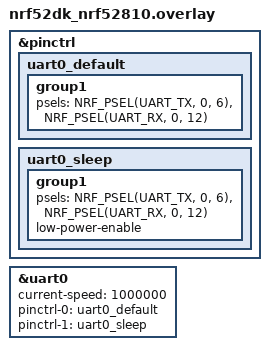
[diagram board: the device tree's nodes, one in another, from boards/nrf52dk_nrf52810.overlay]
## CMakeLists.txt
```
#
# Copyright (c) 2018 Nordic Semiconductor
#
# SPDX-License-Identifier: LicenseRef-Nordic-5-Clause
#
cmake_minimum_required(VERSION 3.20.0)

find_package(Zephyr REQUIRED HINTS $ENV{ZEPHYR_BASE})
project(EYE_AD8221)

# NORDIC SDK APP START
target_sources(app PRIVATE
  src/main.c
  src/emg_notch.c
  src/emg_sampler.c
  src/emg_uart_stream.c
  src/emg_ble_stream.c
  src/fatal_hook.c
)

# NORDIC SDK APP END
```

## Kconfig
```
#
# Copyright (c) 2018 Nordic Semiconductor
#
# SPDX-License-Identifier: LicenseRef-Nordic-5-Clause
#

source "Kconfig.zephyr"

menu "Nordic LED-Button BLE GATT service sample"

config BT_LBS_SECURITY_ENABLED
	bool "Enable security"
	default y
	select BT_SMP
	select BT_SETTINGS
	select FLASH
	select FLASH_PAGE_LAYOUT
	select FLASH_MAP
	select ZMS if (SOC_FLASH_NRF_RRAM || SOC_FLASH_NRF_MRAM)
	select NVS if !(SOC_FLASH_NRF_RRAM || SOC_FLASH_NRF_MRAM)
	select SETTINGS
	help
	  "Enable BLE security for the LED-Button service"

config EYE_BLE_STREAM_HZ
	int "BLE stream rate (Hz)"
	range 50 1000
	default 200
	help
	  Sample rate in samples/second delivered to the BLE client (may be packed
	  into fewer notifications).

config EYE_BLE_PACKET_HZ
	int "BLE notification packet rate (Hz)"
	range 1 200
	default 1
	help
	  Notification packets per second. Each packet carries multiple samples so
	  that EYE_BLE_STREAM_HZ samples/s are delivered with lower notify rate.

config EYE_BLE_STREAM_DISABLED
	bool "Disable BLE stream queue (debug via UART/RTT only)"
	default n
	help
	  When set, the sampler will not enqueue samples for BLE streaming, avoiding
	  queue drops while debugging over UART/RTT.

config EYE_ADC_SAMPLE_RATE_HZ
	int "ADC sample rate (Hz)"
	range 500 4000
	default 1000
	help
	  ADC sampling rate used on the MCU. Must be a multiple of EYE_BLE_STREAM_HZ.

config EYE_NOTCH_FREQ_HZ
	int "Notch center frequency (Hz)"
	range 50 60
	default 50
	help
	  50 Hz or 60 Hz mains notch.

config EYE_NOTCH_ENABLED
	bool "Enable notch filter"
	default y
	help
	  Enable/disable the MCU-side 2nd order IIR notch filter. Disabling keeps
	  the code available but streams raw (unfiltered) samples.

config EYE_NOTCH_Q
	int "Notch Q (approx)"
	range 20 35
	default 30
	help
	  Notch filter Q. Coefficients are precomputed for Q=20/25/30/35 and the
	  closest value is selected.

config EYE_NOTCH_DOUBLE
	bool "Apply notch twice (4th-order equivalent)"
	default n
	depends on EYE_NOTCH_ENABLED
	help
	  If enabled, run the notch filter twice (cascaded) for deeper 50/60 Hz
	  rejection at the cost of a slightly wider notch and more attenuation
	  around the center frequency.

config EYE_ENVELOPE_ENABLED
	bool "Compute envelope/energy (rectified + low-pass) before streaming"
	default y
	help
	  Rectify (abs) the centered ADC sample and apply a first-order IIR
	  low-pass to obtain an envelope/energy channel before decimation.
	  This lowers bandwidth while preserving EMG strength trends.

config EYE_ENVELOPE_TAU_SHIFT
	int "Envelope IIR shift (time constant)"
	range 3 8
	default 5
	depends on EYE_ENVELOPE_ENABLED
	help
	  IIR update: env = env + ((rect - env) >> shift). Smaller shift = faster
	  response (shorter time constant). At 2 kHz, shift 5 ~16 ms.

config EYE_UART_STREAM
	bool "Stream ADC to UART for VOFA+"
	default n
	help
	  Stream raw ADC samples over the console UART using VOFA+ JustFloat
	  protocol (float32 + 0x0000807F tail). Note: do not mix with text logs.

config EYE_UART_STREAM_CENTERED
	bool "UART stream centered values"
	default n
	depends on EYE_UART_STREAM
	help
	  If enabled, stream (raw - 2048) as float; otherwise stream raw (0..4095).

config EYE_UART_STREAM_HZ
	int "UART stream frame rate (Hz)"
	range 10 2000
	default 500
	depends on EYE_UART_STREAM
	help
	  VOFA+ frame rate.

config EYE_UART_STREAM_CHANNELS
	int "UART stream channels"
	range 2 3
	default 3
	depends on EYE_UART_STREAM
	help
	  Fixed to 2-3 channels for VOFA+:
	  2: CH1 raw ADC, CH2 filtered/decimated
	  3: CH1 raw, CH2 filtered/decimated, CH3 notch-filtered (50/60 Hz)

config EYE_BLE_CONN_INTERVAL_MIN
	int "BLE conn interval min (1.25ms units)"
	range 6 3200
	default 6
	help
	  Requested minimum connection interval (8 => 10ms).

config EYE_BLE_CONN_INTERVAL_MAX
	int "BLE conn interval max (1.25ms units)"
	range 6 3200
	default 12
	help
	  Requested maximum connection interval (8 => 10ms).

endmenu
```

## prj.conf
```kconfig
#
# Copyright (c) 2018 Nordic Semiconductor
#
# SPDX-License-Identifier: LicenseRef-Nordic-5-Clause
#
CONFIG_BT=y
CONFIG_BT_PERIPHERAL=y
CONFIG_BT_DEVICE_NAME="EYE_AD8221"
CONFIG_BT_SMP=n
CONFIG_BT_SETTINGS=n
CONFIG_BT_LBS_SECURITY_ENABLED=n

# Keep the connection interval from being auto-changed to slow defaults.
CONFIG_BT_GAP_AUTO_UPDATE_CONN_PARAMS=n
CONFIG_BT_GAP_PERIPHERAL_PREF_PARAMS=y
CONFIG_BT_PERIPHERAL_PREF_MIN_INT=6
CONFIG_BT_PERIPHERAL_PREF_MAX_INT=12
CONFIG_BT_PERIPHERAL_PREF_LATENCY=0
CONFIG_BT_PERIPHERAL_PREF_TIMEOUT=400

# SAADC via NRFX (timer + PPI driven)
CONFIG_ADC=n
CONFIG_NRFX_SAADC=y
CONFIG_NRFX_TIMER2=y
CONFIG_NRFX_PPI=y

# BLE peripheral helpers
CONFIG_DK_LIBRARY=y

CONFIG_SYSTEM_WORKQUEUE_STACK_SIZE=1024
CONFIG_ISR_STACK_SIZE=1536

# UART (P0.06 TX / P0.12 RX via overlay) used for VOFA+ binary stream
CONFIG_SERIAL=y
CONFIG_NRFX_UARTE0=y

# Streaming + filtering (defaults)
CONFIG_EYE_BLE_STREAM_HZ=4000
CONFIG_EYE_BLE_PACKET_HZ=100
CONFIG_EYE_BLE_STREAM_DISABLED=n
CONFIG_EYE_ADC_SAMPLE_RATE_HZ=4000
CONFIG_EYE_NOTCH_FREQ_HZ=50
CONFIG_EYE_NOTCH_ENABLED=y
CONFIG_EYE_NOTCH_Q=25
CONFIG_EYE_NOTCH_DOUBLE=y
CONFIG_EYE_ENVELOPE_ENABLED=y
CONFIG_EYE_ENVELOPE_TAU_SHIFT=5
CONFIG_EYE_BLE_CONN_INTERVAL_MIN=6
CONFIG_EYE_BLE_CONN_INTERVAL_MAX=12

# VOFA+ UART stream (raw ADC + filtered sample)
CONFIG_EYE_UART_STREAM=y
CONFIG_EYE_UART_STREAM_CENTERED=n
CONFIG_EYE_UART_STREAM_HZ=2000
CONFIG_EYE_UART_STREAM_CHANNELS=3

# Keep UART clean for VOFA+ binary stream: route text output to RTT instead.
CONFIG_USE_SEGGER_RTT=y
CONFIG_RTT_CONSOLE=y
CONFIG_SEGGER_RTT_BUFFER_SIZE_UP=512
CONFIG_SEGGER_RTT_MAX_NUM_UP_BUFFERS=4
CONFIG_SEGGER_RTT_MAX_NUM_DOWN_BUFFERS=1
CONFIG_CONSOLE=y
CONFIG_PRINTK=y
CONFIG_UART_CONSOLE=n
CONFIG_BOOT_BANNER=n

# Increase TX capacity to sustain high notification rates even if the central
# selects a longer connection interval.
CONFIG_BT_CONN_TX_MAX=6
CONFIG_BT_L2CAP_TX_BUF_COUNT=6
CONFIG_BT_ATT_TX_COUNT=6
CONFIG_BT_BUF_ACL_TX_COUNT=6
CONFIG_BT_BUF_EVT_RX_COUNT=8

# Debug: crash visibility and assertions
CONFIG_FAULT_DUMP=2
CONFIG_ASSERT=y
CONFIG_DEBUG_OPTIMIZATIONS=y
CONFIG_RESET_ON_FATAL_ERROR=n
CONFIG_THREAD_STACK_INFO=y
CONFIG_STACK_SENTINEL=n
```

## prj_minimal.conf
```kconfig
# BEGIN Configurations from basic/minimal

CONFIG_BT=y
CONFIG_BT_PERIPHERAL=y
CONFIG_BT_DEVICE_NAME="EYE_AD8221"
CONFIG_BT_SMP=n
CONFIG_BT_SETTINGS=n
CONFIG_BT_LBS_SECURITY_ENABLED=n

# SAADC via NRFX (timer + PPI driven)
CONFIG_ADC=n
CONFIG_NRFX_SAADC=y
CONFIG_NRFX_TIMER2=y
CONFIG_NRFX_PPI=y
CONFIG_EYE_ADC_SAMPLE_RATE_HZ=2000

CONFIG_DK_LIBRARY=y

# Drivers and peripherals
CONFIG_I2C=n
CONFIG_WATCHDOG=n
CONFIG_GPIO=n
CONFIG_SPI=n
CONFIG_SERIAL=y

# Power management

# Interrupts
CONFIG_DYNAMIC_INTERRUPTS=n
CONFIG_IRQ_OFFLOAD=n

# Memory protection
CONFIG_THREAD_STACK_INFO=n
CONFIG_THREAD_CUSTOM_DATA=n
CONFIG_FPU=n

# Boot
CONFIG_NCS_BOOT_BANNER=n
CONFIG_BOOT_BANNER=n
CONFIG_BOOT_DELAY=0

# Console: keep UART0 clean for VOFA+ stream, route text output to RTT instead.
CONFIG_USE_SEGGER_RTT=y
CONFIG_RTT_CONSOLE=y
CONFIG_CONSOLE=y
CONFIG_PRINTK=y
CONFIG_UART_CONSOLE=n
CONFIG_EARLY_CONSOLE=n

# Build
CONFIG_SIZE_OPTIMIZATIONS=y

# ARM
CONFIG_ARM_MPU=n
# END Configurations from basic/minimal

# In order to correctly tune the stack sizes for the threads the following
# Configurations can enabled to print the current use:
# CONFIG_THREAD_NAME=y
# CONFIG_THREAD_ANALYZER=y
# CONFIG_THREAD_ANALYZER_AUTO=y
# CONFIG_THREAD_ANALYZER_RUN_UNLOCKED=y
# CONFIG_THREAD_ANALYZER_USE_PRINTK=y
# CONFIG_CONSOLE=y
# CONFIG_UART_CONSOLE=y
# CONFIG_SERIAL=y
# CONFIG_PRINTK=y

# Example output of thread analyzer
# SDC RX              : unused 816 usage 208 / 1024 (20 %)
# BT RX               : unused 1784 usage 416 / 2200 (18 %)
# BT TX               : unused 992 usage 544 / 1536 (35 %)
# thread_analyzer     : unused 136 usage 376 / 512 (73 %)
# sysworkq            : unused 1824 usage 224 / 2048 (10 %)
# MPSL signal         : unused 520 usage 504 / 1024 (49 %)
# idle 00             : unused 192 usage 64 / 256 (25 %)
# main                : unused 136 usage 888 / 1024 (86 %)
# Configurations set based on thread analyzer output.
CONFIG_BT_RX_STACK_SIZE=1024
CONFIG_BT_HCI_TX_STACK_SIZE_WITH_PROMPT=y
CONFIG_BT_HCI_TX_STACK_SIZE=640
CONFIG_SYSTEM_WORKQUEUE_STACK_SIZE=1536
CONFIG_MPSL_WORK_STACK_SIZE=640
CONFIG_IDLE_STACK_SIZE=128
CONFIG_ISR_STACK_SIZE=1024

# Disable features not needed
CONFIG_TIMESLICING=n
CONFIG_COMMON_LIBC_MALLOC=n
CONFIG_LOG=n
CONFIG_ASSERT=n

# Disable Bluetooth features not needed
CONFIG_BT_DEBUG_NONE=y
CONFIG_BT_ASSERT=n
CONFIG_BT_DATA_LEN_UPDATE=n
CONFIG_BT_PHY_UPDATE=n
CONFIG_BT_GATT_CACHING=n
CONFIG_BT_GATT_SERVICE_CHANGED=n
CONFIG_BT_GAP_AUTO_UPDATE_CONN_PARAMS=n
CONFIG_BT_GAP_PERIPHERAL_PREF_PARAMS=y
CONFIG_BT_PERIPHERAL_PREF_MIN_INT=6
CONFIG_BT_PERIPHERAL_PREF_MAX_INT=12
CONFIG_BT_PERIPHERAL_PREF_LATENCY=0
CONFIG_BT_PERIPHERAL_PREF_TIMEOUT=400
CONFIG_BT_SETTINGS_CCC_LAZY_LOADING=n
CONFIG_BT_HCI_VS=n

# Disable Bluetooth controller features not needed
CONFIG_BT_CTLR_PRIVACY=n
CONFIG_BT_CTLR_PHY_2M=n

# VOFA+ UART stream (raw ADC + BLE sample + BLE sent + err)
CONFIG_EYE_UART_STREAM=y
CONFIG_EYE_UART_STREAM_CENTERED=n
CONFIG_EYE_UART_STREAM_HZ=2000
CONFIG_EYE_UART_STREAM_CHANNELS=3

# BLE stream/packet rates
CONFIG_EYE_BLE_STREAM_HZ=200
CONFIG_EYE_BLE_PACKET_HZ=50

CONFIG_EYE_NOTCH_FREQ_HZ=50
CONFIG_EYE_NOTCH_ENABLED=y
CONFIG_EYE_NOTCH_Q=25
CONFIG_EYE_NOTCH_DOUBLE=n
CONFIG_EYE_ENVELOPE_ENABLED=y
CONFIG_EYE_ENVELOPE_TAU_SHIFT=5

# Reduce Bluetooth buffers
CONFIG_BT_BUF_EVT_DISCARDABLE_COUNT=1
CONFIG_BT_BUF_EVT_DISCARDABLE_SIZE=43
CONFIG_BT_BUF_EVT_RX_COUNT=8

CONFIG_BT_CONN_TX_MAX=6
CONFIG_BT_L2CAP_TX_BUF_COUNT=6
CONFIG_BT_ATT_TX_COUNT=6
CONFIG_BT_BUF_ACL_TX_COUNT=6
CONFIG_BT_BUF_ACL_TX_SIZE=27
```

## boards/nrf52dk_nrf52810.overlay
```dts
#include <zephyr/dt-bindings/pinctrl/nrf-pinctrl.h>

&pinctrl {
	uart0_default: uart0_default {
		group1 {
			psels = <NRF_PSEL(UART_TX, 0, 6)>,
				<NRF_PSEL(UART_RX, 0, 12)>;
		};
	};

	uart0_sleep: uart0_sleep {
		group1 {
			psels = <NRF_PSEL(UART_TX, 0, 6)>,
				<NRF_PSEL(UART_RX, 0, 12)>;
			low-power-enable;
		};
	};
};

&uart0 {
	status = "okay";
	current-speed = <1000000>;
	pinctrl-0 = <&uart0_default>;
	pinctrl-1 = <&uart0_sleep>;
	pinctrl-names = "default", "sleep";
};
```

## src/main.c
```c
/*
 * Copyright (c) 2018 Nordic Semiconductor ASA
 *
 * SPDX-License-Identifier: LicenseRef-Nordic-5-Clause
 */

#include <zephyr/types.h>
#include <stddef.h>
#include <string.h>
#include <errno.h>
#include <zephyr/sys/printk.h>
#include <zephyr/sys/byteorder.h>
#include <zephyr/sys/util.h>
#include <zephyr/kernel.h>

#include <zephyr/bluetooth/bluetooth.h>
#include <zephyr/bluetooth/hci.h>
#include <zephyr/bluetooth/conn.h>
#include <zephyr/bluetooth/uuid.h>
#include <zephyr/bluetooth/gatt.h>

#include <dk_buttons_and_leds.h>

#include "emg_sampler.h"
#include "emg_uart_stream.h"
#include "emg_ble_stream.h"

/*
 * Application entry point.
 *
 * Responsibilities:
 * - Initialize BLE GATT service for single-sample read/notify + stream notify.
 * - Start the SAADC sampling pipeline and UART binary streaming.
 * - Maintain BLE advertising/connection state and send periodic stats.
 */
#define DEVICE_NAME             CONFIG_BT_DEVICE_NAME
#define DEVICE_NAME_LEN         (sizeof(DEVICE_NAME) - 1)
#define DEVICE_NAME_SHORT_MAX   8
#define DEVICE_NAME_SHORT_LEN   MIN(DEVICE_NAME_LEN, DEVICE_NAME_SHORT_MAX)


#define RUN_STATUS_LED          DK_LED1
#define CON_STATUS_LED          DK_LED2
#define RUN_LED_BLINK_INTERVAL  1000

static struct k_work adv_work;

#define NOTIFY_INTERVAL_MS_DEFAULT  (1000 / CONFIG_EYE_BLE_PACKET_HZ)
#define NOTIFY_INTERVAL_MS_MIN      NOTIFY_INTERVAL_MS_DEFAULT

BUILD_ASSERT(CONFIG_EYE_BLE_STREAM_HZ % CONFIG_EYE_BLE_PACKET_HZ == 0,
	     "EYE_BLE_STREAM_HZ must be a multiple of EYE_BLE_PACKET_HZ");
#define STREAM_SAMPLES_PER_PACKET   (CONFIG_EYE_BLE_STREAM_HZ / CONFIG_EYE_BLE_PACKET_HZ)

static uint16_t notify_interval_ms = NOTIFY_INTERVAL_MS_DEFAULT;
static struct k_work_delayable notify_work;
static uint32_t last_stats_uptime_ms;
static uint32_t stat_notify_attempts;
static uint32_t stat_notify_ok;
static uint32_t stat_notify_err;
static uint32_t last_sampler_log_ms;

/* BLE UUIDs */
#define BT_UUID_EYE_SVC_VAL \
	BT_UUID_128_ENCODE(0x0000ad82, 0x1212, 0xefde, 0x1523, 0x785feabcd123)

#define BT_UUID_EYE_ADC_VAL \
	BT_UUID_128_ENCODE(0x0000ad83, 0x1212, 0xefde, 0x1523, 0x785feabcd123)

#define BT_UUID_EYE_CFG_VAL \
	BT_UUID_128_ENCODE(0x0000ad84, 0x1212, 0xefde, 0x1523, 0x785feabcd123)

#define BT_UUID_EYE_STREAM_VAL \
	BT_UUID_128_ENCODE(0x0000ad85, 0x1212, 0xefde, 0x1523, 0x785feabcd123)

#define BT_UUID_EYE_SVC  BT_UUID_DECLARE_128(BT_UUID_EYE_SVC_VAL)
#define BT_UUID_EYE_ADC  BT_UUID_DECLARE_128(BT_UUID_EYE_ADC_VAL)
#define BT_UUID_EYE_CFG  BT_UUID_DECLARE_128(BT_UUID_EYE_CFG_VAL)
#define BT_UUID_EYE_STREAM  BT_UUID_DECLARE_128(BT_UUID_EYE_STREAM_VAL)

static bool notify_enabled;
static bool stream_notify_enabled;
static struct bt_conn *default_conn;

static void request_fast_conn_params(struct bt_conn *conn)
{
	struct bt_le_conn_param param = {
		.interval_min = CONFIG_EYE_BLE_CONN_INTERVAL_MIN,
		.interval_max = CONFIG_EYE_BLE_CONN_INTERVAL_MAX,
		.latency = 0,
		.timeout = 400,
	};

	int err = bt_conn_le_param_update(conn, &param);
	if (err) {
		printk("Conn param update request failed (err %d)\n", err);
	}
}

static const struct bt_data ad[] = {
	BT_DATA_BYTES(BT_DATA_FLAGS, (BT_LE_AD_GENERAL | BT_LE_AD_NO_BREDR)),
	BT_DATA_BYTES(BT_DATA_UUID128_ALL, BT_UUID_EYE_SVC_VAL),
	BT_DATA(BT_DATA_NAME_SHORTENED, DEVICE_NAME, DEVICE_NAME_SHORT_LEN),
};

static const struct bt_data sd[] = {
	BT_DATA(BT_DATA_NAME_COMPLETE, DEVICE_NAME, DEVICE_NAME_LEN),
};

static void notify_work_handler(struct k_work *work);

/*
 * CCC handlers toggle notifications for the single-sample and stream
 * characteristics. Both of them share the same notify work item and interval.
 */
static void ccc_cfg_changed(const struct bt_gatt_attr *attr, uint16_t value)
{
	notify_enabled = (value == BT_GATT_CCC_NOTIFY);

	if (!default_conn) {
		return;
	}

	if (!notify_enabled || notify_interval_ms == 0) {
		(void)k_work_cancel_delayable(&notify_work);
		return;
	}

	request_fast_conn_params(default_conn);
	k_work_reschedule(&notify_work, K_NO_WAIT);
}

static void stream_ccc_cfg_changed(const struct bt_gatt_attr *attr, uint16_t value)
{
	ARG_UNUSED(attr);
	stream_notify_enabled = (value == BT_GATT_CCC_NOTIFY);

	if (!default_conn) {
		return;
	}

	if (!stream_notify_enabled || notify_interval_ms == 0) {
		(void)k_work_cancel_delayable(&notify_work);
		return;
	}

	request_fast_conn_params(default_conn);
	k_work_reschedule(&notify_work, K_NO_WAIT);
}

static ssize_t read_adc(struct bt_conn *conn, const struct bt_gatt_attr *attr,
			void *buf, uint16_t len, uint16_t offset)
{
	/* Read handler returns the latest filtered sample (little-endian). */
	uint16_t sample = emg_sampler_get_latest_sample_u16();
	uint16_t sample_le = sys_cpu_to_le16(sample);

	return bt_gatt_attr_read(conn, attr, buf, len, offset, &sample_le,
				 sizeof(sample_le));
}

static ssize_t write_cfg(struct bt_conn *conn, const struct bt_gatt_attr *attr,
			 const void *buf, uint16_t len, uint16_t offset,
			 uint8_t flags)
{
	if (offset != 0) {
		return BT_GATT_ERR(BT_ATT_ERR_INVALID_OFFSET);
	}

	if (len != sizeof(uint16_t)) {
		return BT_GATT_ERR(BT_ATT_ERR_INVALID_ATTRIBUTE_LEN);
	}

	uint16_t interval = sys_get_le16(buf);

	/* Clamp to a safe interval range to avoid flooding or slowing down too far. */
	if (interval != 0 && interval < NOTIFY_INTERVAL_MS_MIN) {
		interval = NOTIFY_INTERVAL_MS_MIN;
	}

	/* Keep MCU default rate unless the client explicitly asks for faster. */
	if (interval != 0 && interval > NOTIFY_INTERVAL_MS_DEFAULT) {
		interval = NOTIFY_INTERVAL_MS_DEFAULT;
	}

	notify_interval_ms = interval;

	if (!default_conn) {
		return len;
	}

	if (notify_interval_ms == 0 || !notify_enabled) {
		(void)k_work_cancel_delayable(&notify_work);
	} else {
		k_work_reschedule(&notify_work, K_NO_WAIT);
	}

	return len;
}

BT_GATT_SERVICE_DEFINE(eye_svc,
	BT_GATT_PRIMARY_SERVICE(BT_UUID_EYE_SVC),
	BT_GATT_CHARACTERISTIC(BT_UUID_EYE_ADC, BT_GATT_CHRC_READ | BT_GATT_CHRC_NOTIFY,
			       BT_GATT_PERM_READ, read_adc, NULL, NULL),
	BT_GATT_CCC(ccc_cfg_changed, BT_GATT_PERM_READ | BT_GATT_PERM_WRITE),
	BT_GATT_CHARACTERISTIC(BT_UUID_EYE_CFG, BT_GATT_CHRC_WRITE,
			       BT_GATT_PERM_WRITE, NULL, write_cfg, NULL),
	BT_GATT_CHARACTERISTIC(BT_UUID_EYE_STREAM, BT_GATT_CHRC_NOTIFY,
			       BT_GATT_PERM_NONE, NULL, NULL, NULL),
	BT_GATT_CCC(stream_ccc_cfg_changed, BT_GATT_PERM_READ | BT_GATT_PERM_WRITE),
);

static void notify_work_handler(struct k_work *work)
{
	ARG_UNUSED(work);

	/* Work item is shared by both notify paths and reschedules itself. */
	if (!default_conn || notify_interval_ms == 0 || (!notify_enabled && !stream_notify_enabled)) {
		return;
	}

	uint16_t effective_interval_ms = notify_interval_ms;
	if (!stream_notify_enabled && notify_enabled && (notify_interval_ms == NOTIFY_INTERVAL_MS_DEFAULT)) {
		effective_interval_ms = MAX(1U, (1000U / CONFIG_EYE_BLE_STREAM_HZ));
	}

	uint32_t now_ms = (uint32_t)k_uptime_get_32();
	if (last_stats_uptime_ms == 0) {
		last_stats_uptime_ms = now_ms;
	}
	if (!IS_ENABLED(CONFIG_UART_CONSOLE) && (now_ms - last_stats_uptime_ms) >= 1000U) {
		printk("BLE notify: interval=%ums attempts=%u ok=%u err=%u (target=%uHz)\n",
		       effective_interval_ms, stat_notify_attempts, stat_notify_ok,
		       stat_notify_err, CONFIG_EYE_BLE_STREAM_HZ);
		printk("BLE ccc: ad83=%u ad85=%u mtu=%u qdrop=%u nerr=%u clip_lo=%u clip_hi=%u\n",
		       notify_enabled ? 1 : 0,
		       stream_notify_enabled ? 1 : 0,
		       bt_gatt_get_mtu(default_conn),
		       emg_sampler_get_stream_drop_count(),
		       emg_ble_stream_get_notify_err(),
		       emg_sampler_get_clip_lo(),
		       emg_sampler_get_clip_hi());
		stat_notify_attempts = 0;
		stat_notify_ok = 0;
		stat_notify_err = 0;
		last_stats_uptime_ms = now_ms;
	}

	if (stream_notify_enabled) {
		/*
		 * Stream notify mode:
		 * - Pulls a packet of samples from the sampler stream queue.
		 * - Chunks the packet to fit the current MTU.
		 * - Spreads chunks across the notify interval to reduce bursts.
		 */
		static uint32_t period_end_ms;
		static uint32_t staged_first_seq;
		static struct emg_stream_pair staged_samples[STREAM_SAMPLES_PER_PACKET];
		static uint32_t staged_count;
		static uint32_t staged_off;

		const uint16_t mtu = bt_gatt_get_mtu(default_conn);
		const uint16_t max_payload = (mtu > 3U) ? (mtu - 3U) : 0U;
		const uint16_t max_samples_per_notify =
			(max_payload > 5U) ? (uint16_t)((max_payload - 5U) / 4U) : 0U;

		if (max_samples_per_notify == 0U) {
			k_work_schedule(&notify_work, K_MSEC(notify_interval_ms));
			return;
		}

		/* Stage a new packet when the previous one has been fully sent. */
		if (staged_off >= staged_count) {
			if (period_end_ms != 0U && (int32_t)(now_ms - period_end_ms) < 0) {
				k_work_schedule(&notify_work, K_MSEC(period_end_ms - now_ms));
				return;
			}

			staged_off = 0;
			staged_count = emg_sampler_pop_stream(&staged_first_seq, staged_samples,
							     STREAM_SAMPLES_PER_PACKET);
			if (staged_count == 0U) {
				period_end_ms = 0U;
				k_work_schedule(&notify_work, K_MSEC(5));
				return;
			}
			period_end_ms = now_ms + effective_interval_ms;
		}

		const uint32_t remaining = staged_count - staged_off;
		const uint32_t chunk = MIN(remaining, (uint32_t)max_samples_per_notify);

		uint8_t payload[5 + 4 * STREAM_SAMPLES_PER_PACKET];
		const uint32_t first_seq = staged_first_seq + staged_off;

		sys_put_le32(first_seq, &payload[0]);
		payload[4] = (uint8_t)chunk;
		for (uint32_t i = 0; i < chunk; i++) {
			const struct emg_stream_pair *pair = &staged_samples[staged_off + i];
			sys_put_le16(pair->filtered, &payload[5 + 4 * i]);
			sys_put_le16(pair->envelope, &payload[5 + 4 * i + 2]);
		}

		stat_notify_attempts++;
		int err = bt_gatt_notify(default_conn, &eye_svc.attrs[7], payload, 5 + 2 * chunk);
		if (err) {
			stat_notify_err++;
			emg_ble_stream_note_notify_err();

			if (err == -ENOMEM || err == -EAGAIN) {
				k_work_schedule(&notify_work, K_MSEC(2));
				return;
			}

			k_work_schedule(&notify_work, K_MSEC(notify_interval_ms));
			return;
		}

		stat_notify_ok++;
		emg_ble_stream_note_notify_ok(chunk);
		emg_ble_stream_note_sent(first_seq + chunk - 1U,
					 staged_samples[staged_off + chunk - 1U].filtered);
		staged_off += chunk;

		if (staged_off < staged_count) {
			now_ms = (uint32_t)k_uptime_get_32();
			const uint32_t rem_samples = staged_count - staged_off;
			const uint32_t chunks_left =
				(rem_samples + max_samples_per_notify - 1U) / max_samples_per_notify;
			const uint32_t time_left_ms =
				(period_end_ms != 0U && (int32_t)(period_end_ms - now_ms) > 0)
					? (period_end_ms - now_ms)
					: 1U;
			const uint32_t chunk_period_ms = MAX(1U, time_left_ms / MAX(1U, chunks_left));
			k_work_schedule(&notify_work, K_MSEC(chunk_period_ms));
			return;
		}

		now_ms = (uint32_t)k_uptime_get_32();
		if (period_end_ms != 0U && (int32_t)(now_ms - period_end_ms) < 0) {
			k_work_schedule(&notify_work, K_MSEC(period_end_ms - now_ms));
		} else {
			k_work_schedule(&notify_work, K_NO_WAIT);
		}
		return;
	} else if (notify_enabled) {
		/* Single-sample notify mode (simple characteristic notify). */
		uint16_t sample = emg_sampler_get_latest_sample_u16();
		uint16_t sample_le = sys_cpu_to_le16(sample);

		stat_notify_attempts++;
		int err = bt_gatt_notify(default_conn, &eye_svc.attrs[2],
					 &sample_le, sizeof(sample_le));
		if (err) {
			stat_notify_err++;
		} else {
			stat_notify_ok++;
		}
	}

	k_work_schedule(&notify_work, K_MSEC(effective_interval_ms));
}

static void adv_work_handler(struct k_work *work)
{
	/* Deferred advertising start to keep startup ordering clean. */
	int err = bt_le_adv_start(BT_LE_ADV_CONN_FAST_2, ad, ARRAY_SIZE(ad), sd, ARRAY_SIZE(sd));

	if (err) {
		printk("Advertising failed to start (err %d)\n", err);
		return;
	}

	printk("Advertising successfully started\n");
}

static void advertising_start(void)
{
	k_work_submit(&adv_work);
}

static void connected(struct bt_conn *conn, uint8_t err)
{
	if (err) {
		printk("Connection failed, err 0x%02x %s\n", err, bt_hci_err_to_str(err));
		return;
	}

	printk("Connected\n");

	default_conn = bt_conn_ref(conn);
	dk_set_led_on(CON_STATUS_LED);

	request_fast_conn_params(conn);

	/* nRF52810 does not support LE 2M PHY; skip bt_conn_le_phy_update to avoid link error. */
}

static void disconnected(struct bt_conn *conn, uint8_t reason)
{
	printk("Disconnected, reason 0x%02x %s\n", reason, bt_hci_err_to_str(reason));

	notify_enabled = false;
	if (default_conn) {
		bt_conn_unref(default_conn);
		default_conn = NULL;
	}
	(void)k_work_cancel_delayable(&notify_work);

	dk_set_led_off(CON_STATUS_LED);
}

static void recycled_cb(void)
{
	printk("Connection object available from previous conn. Disconnect is complete!\n");
	advertising_start();
}

#if defined(CONFIG_BT_CONN)
static void le_param_updated(struct bt_conn *conn, uint16_t interval,
			     uint16_t latency, uint16_t timeout)
{
	ARG_UNUSED(conn);
	printk("LE params updated: interval %u (1.25ms), latency %u, timeout %u (10ms)\n",
	       interval, latency, timeout);
}
#endif

#ifdef CONFIG_BT_LBS_SECURITY_ENABLED
static void security_changed(struct bt_conn *conn, bt_security_t level,
			     enum bt_security_err err)
{
	char addr[BT_ADDR_LE_STR_LEN];

	bt_addr_le_to_str(bt_conn_get_dst(conn), addr, sizeof(addr));

	if (!err) {
		printk("Security changed: %s level %u\n", addr, level);
	} else {
		printk("Security failed: %s level %u err %d %s\n", addr, level, err,
		       bt_security_err_to_str(err));
	}
}
#endif

BT_CONN_CB_DEFINE(conn_callbacks) = {
	.connected        = connected,
	.disconnected     = disconnected,
	.recycled         = recycled_cb,
#if defined(CONFIG_BT_CONN)
	.le_param_updated = le_param_updated,
#endif
};

int main(void)
{
	int blink_status = 0;
	int err;
	uint32_t now_ms;

	/* Bring up console logging early for power-on visibility. */
	printk("Starting BLE ADC (P0.04) peripheral\n");
	printk("UART0 pins: TX=P0.06 RX=P0.12 (1000000)\n");
	printk("Stream target: %uHz (notify interval %ums)\n",
	       CONFIG_EYE_BLE_STREAM_HZ, NOTIFY_INTERVAL_MS_DEFAULT);
	printk("ADC sample rate: %u Hz\n", CONFIG_EYE_ADC_SAMPLE_RATE_HZ);

	err = dk_leds_init();
	if (err) {
		printk("LEDs init failed (err %d)\n", err);
		return 0;
	}

	err = bt_enable(NULL);
	if (err) {
		printk("Bluetooth init failed (err %d)\n", err);
		return 0;
	}

	printk("Bluetooth initialized\n");

	/* Start the sampling pipeline before enabling streaming outputs. */
	err = emg_sampler_init();
	if (err) {
		printk("Sampler init failed (err %d)\n", err);
		return 0;
	}

	/* UART stream uses a dedicated thread and binary frames. */
	err = emg_uart_stream_init();
	if (err) {
		printk("UART stream init failed (err %d)\n", err);
		return 0;
	}

	k_work_init(&adv_work, adv_work_handler);
	k_work_init_delayable(&notify_work, notify_work_handler);
	advertising_start();

	for (;;) {
		dk_set_led(RUN_STATUS_LED, (++blink_status) % 2);

		/* Once per second: print sampling and queue stats for troubleshooting. */
		now_ms = (uint32_t)k_uptime_get_32();
		if ((now_ms - last_sampler_log_ms) >= 1000U) {
			printk("ADC stats: raw=%u seq=%u drop=%u clip_lo=%u clip_hi=%u\n",
			       emg_sampler_get_latest_raw_u16(),
			       emg_sampler_get_latest_raw_seq(),
			       emg_sampler_get_stream_drop_count(),
			       emg_sampler_get_clip_lo(),
			       emg_sampler_get_clip_hi());
			printk("UART q: drop=%u hwm=%u\n",
			       emg_sampler_get_uart_drop(),
			       emg_sampler_get_uart_hwm());
			last_sampler_log_ms = now_ms;
		}

		k_sleep(K_MSEC(RUN_LED_BLINK_INTERVAL));
	}
}
```

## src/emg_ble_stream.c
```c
/*
 * SPDX-License-Identifier: LicenseRef-Nordic-5-Clause
 */

#include "emg_ble_stream.h"

#include <zephyr/sys/atomic.h>

static atomic_t last_sent_seq;
static atomic_t last_sent_sample_u16;
static atomic_t notify_ok;
static atomic_t notify_err;

/* Track the most recent streamed sequence/sample for diagnostics. */
void emg_ble_stream_note_sent(uint32_t seq, uint16_t sample)
{
	atomic_set(&last_sent_seq, (atomic_val_t)seq);
	atomic_set(&last_sent_sample_u16, (atomic_val_t)sample);
}

/* Accumulate how many samples were acknowledged as notified. */
void emg_ble_stream_note_notify_ok(uint32_t samples)
{
	for (uint32_t i = 0; i < samples; i++) {
		atomic_inc(&notify_ok);
	}
}

/* Count notify failures so we can log BLE link pressure. */
void emg_ble_stream_note_notify_err(void)
{
	atomic_inc(&notify_err);
}

uint32_t emg_ble_stream_get_last_sent_seq(void)
{
	return (uint32_t)atomic_get(&last_sent_seq);
}

uint16_t emg_ble_stream_get_last_sent_sample(void)
{
	return (uint16_t)atomic_get(&last_sent_sample_u16);
}

uint32_t emg_ble_stream_get_notify_ok(void)
{
	return (uint32_t)atomic_get(&notify_ok);
}

uint32_t emg_ble_stream_get_notify_err(void)
{
	return (uint32_t)atomic_get(&notify_err);
}
```

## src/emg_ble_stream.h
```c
/*
 * SPDX-License-Identifier: LicenseRef-Nordic-5-Clause
 */

#pragma once

#include <stdint.h>

/* Record the last sequence/sample that made it onto the BLE stream. */
void emg_ble_stream_note_sent(uint32_t seq, uint16_t sample);
/* Count the number of samples successfully notified. */
void emg_ble_stream_note_notify_ok(uint32_t samples);
/* Count a notify error (link congestion/MTU/backpressure). */
void emg_ble_stream_note_notify_err(void);

/* Diagnostics: last sent sequence/sample and notify stats. */
uint32_t emg_ble_stream_get_last_sent_seq(void);
uint16_t emg_ble_stream_get_last_sent_sample(void);
uint32_t emg_ble_stream_get_notify_ok(void);
uint32_t emg_ble_stream_get_notify_err(void);
```

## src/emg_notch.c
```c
/*
 * SPDX-License-Identifier: LicenseRef-Nordic-5-Clause
 */

#include "emg_notch.h"

#include <stddef.h>
#include <math.h>
#include <zephyr/sys/printk.h>

#ifndef M_PI
#define M_PI 3.14159265358979323846
#endif

struct coeff_entry {
	uint16_t fs_hz;
	uint8_t f0_hz;
	uint8_t q;
	int32_t b0;
	int32_t b1;
	int32_t b2;
	int32_t a1;
	int32_t a2;
};

/*
 * Precomputed biquad notch coefficients in Q30 for:
 * - fs: 1000/2000 Hz
 * - f0: 50/60 Hz
 * - Q: 20/25/30/35
 *
 * Coeffs follow the normalized form:
 *   y[n] = b0*x[n] + b1*x[n-1] + b2*x[n-2] - a1*y[n-1] - a2*y[n-2]
 */
static const struct coeff_entry coeff_table[] = {
	/* fs=1000, f0=50 */
	{ 1000, 50, 20, 1065510304, -2026721036, 1065510304, -2026721036, 1057278784 },
	{ 1000, 50, 25, 1067146496, -2029833258, 1067146496, -2029833258, 1060551168 },
	{ 1000, 50, 30, 1068240085, -2031913388, 1068240085, -2031913388, 1062738346 },
	{ 1000, 50, 35, 1069022593, -2033401807, 1069022593, -2033401807, 1064303363 },

	/* fs=1000, f0=60 */
	{ 1000, 60, 20, 1063950169, -1978471700, 1063950169, -1978471700, 1054158515 },
	{ 1000, 60, 25, 1065894188, -1982086704, 1065894188, -1982086704, 1058046551 },
	{ 1000, 60, 30, 1067194151, -1984504055, 1067194151, -1984504055, 1060646478 },
	{ 1000, 60, 35, 1068124640, -1986234348, 1068124640, -1986234348, 1062507455 },

	/* fs=2000, f0=50 */
	{ 2000, 50, 20, 1069558927, -2112781764, 1069558927, -2112781764, 1065376030 },
	{ 2000, 50, 25, 1070392897, -2114429169, 1070392897, -2114429169, 1067043970 },
	{ 2000, 50, 30, 1070949600, -2115528867, 1070949600, -2115528867, 1068157376 },
	{ 2000, 50, 35, 1071347600, -2116315066, 1071347600, -2116315066, 1068953376 },

	/* fs=2000, f0=60 */
	{ 2000, 60, 20, 1068735298, -2099610116, 1068735298, -2099610116, 1063728773 },
	{ 2000, 60, 25, 1069732865, -2101569910, 1069732865, -2101569910, 1065723906 },
	{ 2000, 60, 30, 1070398945, -2102878473, 1070398945, -2102878473, 1067056065 },
	{ 2000, 60, 35, 1070875224, -2103814159, 1070875224, -2103814159, 1068008624 },
};

/*
 * Pick the closest Q entry for a given fs/f0.
 * The table only supports the fixed fs/f0 pairs above.
 */
static const struct coeff_entry *find_best_coeff(uint32_t fs_hz, uint32_t f0_hz, uint32_t q)
{
	const struct coeff_entry *best = NULL;
	uint32_t best_dist = UINT32_MAX;

	for (size_t i = 0; i < (sizeof(coeff_table) / sizeof(coeff_table[0])); i++) {
		const struct coeff_entry *e = &coeff_table[i];

		if (e->fs_hz != fs_hz || e->f0_hz != f0_hz) {
			continue;
		}

		uint32_t dist = (e->q > q) ? (e->q - q) : (q - e->q);
		if (dist < best_dist) {
			best = e;
			best_dist = dist;
		}
	}

	return best;
}

/*
 * Fallback coefficient compute for arbitrary fs/f0/q (floating-point).
 * The resulting coefficients are converted to Q30 and used in the
 * integer biquad process function.
 */
static int compute_fallback_coeff(struct emg_notch_biquad_q30 *state,
				  uint32_t fs_hz, uint32_t f0_hz, uint32_t q)
{
	if (f0_hz == 0 || fs_hz == 0 || q == 0) {
		return -1;
	}

	double w0 = 2.0 * M_PI * ((double)f0_hz / (double)fs_hz);
	double cos_w0 = cos(w0);
	double alpha = sin(w0) / (2.0 * (double)q);

	double b0 = 1.0;
	double b1 = -2.0 * cos_w0;
	double b2 = 1.0;
	double a0 = 1.0 + alpha;
	double a1 = -2.0 * cos_w0;
	double a2 = 1.0 - alpha;

	/* Normalize by a0 */
	b0 /= a0;
	b1 /= a0;
	b2 /= a0;
	a1 /= a0;
	a2 /= a0;

	const double q30 = (double)(1ULL << 30);
	state->b0 = (int32_t)lrint(b0 * q30);
	state->b1 = (int32_t)lrint(b1 * q30);
	state->b2 = (int32_t)lrint(b2 * q30);
	state->a1 = (int32_t)lrint(a1 * q30);
	state->a2 = (int32_t)lrint(a2 * q30);
	emg_notch_reset(state);

	printk("Notch coeff computed (fs=%u f0=%u q=%u)\n", fs_hz, f0_hz, q);
	return 0;
}

void emg_notch_reset(struct emg_notch_biquad_q30 *state)
{
	if (!state) {
		return;
	}

	state->s1 = 0;
	state->s2 = 0;
}

int emg_notch_configure(struct emg_notch_biquad_q30 *state, uint32_t fs_hz,
			uint32_t f0_hz, uint32_t q)
{
	if (!state) {
		return -1;
	}

	/* Prefer precomputed coefficients when available; fall back otherwise. */
	const struct coeff_entry *e = find_best_coeff(fs_hz, f0_hz, q);
	if (!e) {
		return compute_fallback_coeff(state, fs_hz, f0_hz, q);
	}

	state->b0 = e->b0;
	state->b1 = e->b1;
	state->b2 = e->b2;
	state->a1 = e->a1;
	state->a2 = e->a2;
	emg_notch_reset(state);

	return 0;
}

int32_t emg_notch_process(struct emg_notch_biquad_q30 *state, int32_t x)
{
	/* Direct Form II Transposed, Q30 coefficients, integer samples (Q0). */
	int64_t acc = (int64_t)state->b0 * x + state->s1;
	int32_t y = (int32_t)(acc >> 30);

	state->s1 = (int64_t)state->b1 * x + state->s2 - (int64_t)state->a1 * y;
	state->s2 = (int64_t)state->b2 * x - (int64_t)state->a2 * y;

	return y;
}
```

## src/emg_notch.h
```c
/*
 * SPDX-License-Identifier: LicenseRef-Nordic-5-Clause
 */

#pragma once

#include <stdint.h>

struct emg_notch_biquad_q30 {
	/* Q30 biquad coefficients (normalized). */
	int32_t b0;
	int32_t b1;
	int32_t b2;
	int32_t a1;
	int32_t a2;

	/* Filter state (Direct Form II Transposed). */
	int64_t s1;
	int64_t s2;
};

/* Reset filter state to zero. */
void emg_notch_reset(struct emg_notch_biquad_q30 *state);
/* Configure coefficients for fs/f0/q; uses table or computed fallback. */
int emg_notch_configure(struct emg_notch_biquad_q30 *state, uint32_t fs_hz,
			uint32_t f0_hz, uint32_t q);
/* Process one sample (integer input, integer output). */
int32_t emg_notch_process(struct emg_notch_biquad_q30 *state, int32_t x);
```

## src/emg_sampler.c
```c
/*
 * SPDX-License-Identifier: LicenseRef-Nordic-5-Clause
 */

#include "emg_sampler.h"

#include "emg_notch.h"

#include <errno.h>

#include <zephyr/kernel.h>
#include <zephyr/irq.h>
#include <zephyr/sys/atomic.h>
#include <zephyr/sys/util.h>
#include <zephyr/sys/printk.h>
#include <nrfx_timer.h>
#include <nrfx_ppi.h>
#include <hal/nrf_saadc.h>
#include <nrfx_saadc.h>

#ifndef NRFX_SAADC_CONFIG_IRQ_PRIORITY
#define NRFX_SAADC_CONFIG_IRQ_PRIORITY 6
#endif

/*
 * SAADC sampler pipeline.
 *
 * Data flow:
 * - TIMER2 compares at fs -> PPI -> SAADC SAMPLE
 * - SAADC EasyDMA fills double buffers
 * - SAADC DONE ISR processes samples:
 *   raw -> notch -> high-pass (DC block) -> optional envelope
 * - Outputs:
 *   - Latest values (atomics) for BLE read/notify
 *   - Stream queue (decimated) for BLE streaming
 *   - UART queue (full-rate) for binary streaming
 */

/* SAADC (P0.04 = AIN2 on nRF52) */
#define ADC_CHANNEL_ID      0
#define ADC_INPUT           NRF_SAADC_INPUT_AIN2
#define ADC_RESOLUTION_BITS 12
/* Larger DMA buffer: 200 samples = 100 ms @ 2 kHz (double-buffered). */
#define SAADC_BUF_SIZE      200

static const nrfx_timer_t emg_timer = NRFX_TIMER_INSTANCE(2);
static nrf_ppi_channel_t timer_saadc_ppi;
static nrf_ppi_channel_t saadc_start_ppi;
static int16_t saadc_buf[2][SAADC_BUF_SIZE] __aligned(4);

static struct emg_notch_biquad_q30 notch1;
#if IS_ENABLED(CONFIG_EYE_NOTCH_DOUBLE)
static struct emg_notch_biquad_q30 notch2;
#endif

static atomic_t latest_sample_u16;
static atomic_t latest_seq;
static atomic_t latest_raw_u16;
static atomic_t latest_raw_seq;
static atomic_t latest_notch_u16;
static atomic_t latest_env_u16;
static atomic_t stream_drop;
static atomic_t raw_clip_hi;
static atomic_t raw_clip_lo;
/* Queue for UART to fetch every sample (raw + filtered + notch). */
/* UART queue depth trimmed for RAM headroom. */
K_MSGQ_DEFINE(uart_sample_q, sizeof(struct emg_sample_triple), 192, 4);
static atomic_t uart_q_drop;
static atomic_t uart_q_hwm;

struct stream_item {
	uint32_t seq;
	uint16_t filtered;
	uint16_t envelope;
};

/* Decimated stream queue: keep 64 entries (~512 bytes) to reduce drops. */
K_MSGQ_DEFINE(stream_q, sizeof(struct stream_item), 64, 4);
static atomic_t stream_seq;

static const uint32_t decim = CONFIG_EYE_ADC_SAMPLE_RATE_HZ / CONFIG_EYE_BLE_STREAM_HZ;
static const bool use_envelope = IS_ENABLED(CONFIG_EYE_ENVELOPE_ENABLED);
static const int32_t adc_max = (1 << ADC_RESOLUTION_BITS) - 1;
static uint32_t sample_count;
static int32_t env_iir;
static uint16_t env_last_u16;
static int evt_logged;
static uint16_t active_buf_size = SAADC_BUF_SIZE;
static int drop_log_budget = 8;
/* Simple high-pass (DC-block) on centered filtered signal: y = x - x1 + a*y1 (Q15). */
#define HP_A_Q15 32112 /* ~0.98 */
static int32_t hp_x1;
static int32_t hp_y1;

/*
 * Process one raw sample:
 * - Clip to ADC range, track clip counters.
 * - Notch filter at mains frequency (single or double stage).
 * - DC-block high-pass to remove baseline wander.
 * - Envelope extraction (abs + IIR).
 * - Publish to atomics + queues.
 */
static void process_sample(int16_t raw)
{
	if (raw < 0) {
		raw = 0;
		atomic_inc(&raw_clip_lo);
	} else if (raw > adc_max) {
		raw = adc_max;
		atomic_inc(&raw_clip_hi);
	}

	atomic_set(&latest_raw_u16, (uint16_t)raw);
	atomic_inc(&latest_raw_seq);

	int32_t centered = (int32_t)raw - (1 << (ADC_RESOLUTION_BITS - 1));
	int32_t filtered = emg_notch_process(&notch1, centered);
#if IS_ENABLED(CONFIG_EYE_NOTCH_DOUBLE)
	filtered = emg_notch_process(&notch2, filtered);
#endif
	/* DC-block to keep the baseline near mid-scale. */
	int32_t hp_y = (int32_t)filtered - hp_x1 + ((hp_y1 * HP_A_Q15) >> 15);
	hp_x1 = filtered;
	hp_y1 = hp_y;

	uint16_t notch_u16_fullrate =
		(uint16_t)CLAMP(hp_y + (1 << (ADC_RESOLUTION_BITS - 1)), 0, adc_max);
	atomic_set(&latest_notch_u16, notch_u16_fullrate);

	int32_t env = filtered;
	if (use_envelope) {
		/* Rectify and smooth to approximate signal envelope. */
		int32_t rect = (hp_y < 0) ? -hp_y : hp_y;
		env_iir = env_iir + ((rect - env_iir) >> CONFIG_EYE_ENVELOPE_TAU_SHIFT);
		env = env_iir;
	}

	uint16_t env_u16 = (uint16_t)CLAMP(env, 0, adc_max);
	env_last_u16 = env_u16;

	int32_t uncentered_fullrate = hp_y + (1 << (ADC_RESOLUTION_BITS - 1));
	uint16_t out_fullrate_u16 = (uint16_t)CLAMP(uncentered_fullrate, 0, adc_max);
	atomic_set(&latest_sample_u16, out_fullrate_u16);
	atomic_set(&latest_env_u16, env_u16);

	if (!IS_ENABLED(CONFIG_EYE_BLE_STREAM_DISABLED)) {
		/* Decimate to the BLE stream rate to keep queue size manageable. */
		if ((++sample_count % decim) == 0) {
			uint32_t seq = (uint32_t)atomic_inc(&stream_seq);
			atomic_set(&latest_seq, (atomic_val_t)seq);

			struct stream_item item = {
				.seq = seq,
				.filtered = out_fullrate_u16,
				.envelope = env_last_u16,
			};
			if (k_msgq_put(&stream_q, &item, K_NO_WAIT) != 0) {
				struct stream_item dropped;
				(void)k_msgq_get(&stream_q, &dropped, K_NO_WAIT);
				uint32_t drop_new = (uint32_t)atomic_inc(&stream_drop) + 1U;
				(void)k_msgq_put(&stream_q, &item, K_NO_WAIT);
				if (drop_log_budget > 0) {
					uint32_t used = (uint32_t)k_msgq_num_used_get(&stream_q);
					printk("Stream drop #%u (used=%u seq=%u)\n",
					       drop_new, used, seq);
					drop_log_budget--;
				}
			}
		}
	}

	/* Enqueue full-rate triple for UART; drop oldest if queue is full. */
	struct emg_sample_triple triple = {
		.raw = (uint16_t)raw,
		.filtered = out_fullrate_u16,
		.notch = (uint16_t)atomic_get(&latest_notch_u16),
		.envelope = env_last_u16,
	};
	uint32_t used = (uint32_t)k_msgq_num_used_get(&uart_sample_q);
	if (used > (uint32_t)atomic_get(&uart_q_hwm)) {
		atomic_set(&uart_q_hwm, (atomic_val_t)used);
	}
	if (k_msgq_put(&uart_sample_q, &triple, K_NO_WAIT) != 0) {
		struct emg_sample_triple dropped;
		(void)k_msgq_get(&uart_sample_q, &dropped, K_NO_WAIT);
		(void)k_msgq_put(&uart_sample_q, &triple, K_NO_WAIT);
		atomic_inc(&uart_q_drop);
	}
}

/*
 * SAADC event handler:
 * - Iterate completed buffer and process each sample.
 * - Re-queue the buffer for continuous sampling.
 */
static void saadc_evt_handler(nrfx_saadc_evt_t const *p_event)
{
	switch (p_event->type) {
	case NRFX_SAADC_EVT_DONE:
	{
		int16_t *buf = (int16_t *)p_event->data.done.p_buffer;
		for (uint16_t i = 0; i < p_event->data.done.size; i++) {
			process_sample(buf[i]);
		}
		/* Re-queue the processed buffer. */
		nrfx_err_t berr = nrfx_saadc_buffer_set(p_event->data.done.p_buffer, active_buf_size);
		if (berr != NRFX_SUCCESS && evt_logged < 3) {
			printk("SAADC buffer_set err=0x%x\n", berr);
		}
		if (evt_logged < 3) {
			printk("SAADC evt done size=%u first=%d\n",
			       p_event->data.done.size, buf[0]);
			evt_logged++;
		}
	}
		break;
	default:
		break;
	}
}

int emg_sampler_init(void)
{
	/* Reset state and counters first to avoid stale stats. */
	atomic_set(&latest_sample_u16, 0);
	atomic_set(&latest_seq, 0);
	atomic_set(&latest_raw_u16, 0);
	atomic_set(&latest_raw_seq, 0);
	atomic_set(&stream_seq, 0);
	atomic_set(&latest_notch_u16, 0);
	atomic_set(&latest_env_u16, 0);
	atomic_set(&stream_drop, 0);
	atomic_set(&raw_clip_hi, 0);
	atomic_set(&raw_clip_lo, 0);
	sample_count = 0;
	env_iir = 0;
	env_last_u16 = 0;
	hp_x1 = 0;
	hp_y1 = 0;
	evt_logged = 0;
	drop_log_budget = 8;

	/* Configure notch biquad(s) for the current sample rate. */
	int err = emg_notch_configure(&notch1, CONFIG_EYE_ADC_SAMPLE_RATE_HZ,
				      CONFIG_EYE_NOTCH_FREQ_HZ, CONFIG_EYE_NOTCH_Q);
	if (err) {
		return -EINVAL;
	}
#if IS_ENABLED(CONFIG_EYE_NOTCH_DOUBLE)
	err = emg_notch_configure(&notch2, CONFIG_EYE_ADC_SAMPLE_RATE_HZ,
				  CONFIG_EYE_NOTCH_FREQ_HZ, CONFIG_EYE_NOTCH_Q);
	if (err) {
		return -EINVAL;
	}
#endif

	err = nrfx_saadc_init(NRFX_SAADC_CONFIG_IRQ_PRIORITY);
	if (err != NRFX_SUCCESS) {
		printk("SAADC init err=0x%x\n", err);
		return -EIO;
	}

	/* Explicitly hook SAADC IRQ to avoid spurious interrupt (IRQ 7).
	 * Use a valid Zephyr priority (0-3 on nRF52); nrfx defaults are out of range here.
	 */
	IRQ_CONNECT(SAADC_IRQn, 1, nrfx_saadc_irq_handler, NULL, 0);
	irq_enable(SAADC_IRQn);

	/* Single-ended channel on AIN2 with internal reference. */
	nrfx_saadc_channel_t ch_cfg = NRFX_SAADC_DEFAULT_CHANNEL_SE(ADC_INPUT, ADC_CHANNEL_ID);
	ch_cfg.channel_config.gain = NRF_SAADC_GAIN1_5;
	ch_cfg.channel_config.acq_time = NRF_SAADC_ACQTIME_20US;
	ch_cfg.channel_config.reference = NRF_SAADC_REFERENCE_INTERNAL;
	err = nrfx_saadc_channels_config(&ch_cfg, 1);
	if (err != NRFX_SUCCESS) {
		printk("SAADC channel cfg err=0x%x\n", err);
		return -EIO;
	}

	printk("SAADC cfg ok: gain=1/6 acq=20us bufsize=%u\n", SAADC_BUF_SIZE);
	printk("Sampler init: fs=%u decim=%u queue=%u\n",
	       CONFIG_EYE_ADC_SAMPLE_RATE_HZ, (unsigned int)decim, 40U);

	/* Advanced mode lets us use EasyDMA buffers + event callback. */
	nrfx_saadc_adv_config_t adv_cfg = NRFX_SAADC_DEFAULT_ADV_CONFIG;
	adv_cfg.oversampling = NRF_SAADC_OVERSAMPLE_DISABLED;
	adv_cfg.burst = NRF_SAADC_BURST_DISABLED;
	adv_cfg.internal_timer_cc = 0;
	adv_cfg.start_on_end = false;
	err = nrfx_saadc_advanced_mode_set(BIT(ADC_CHANNEL_ID),
					   NRF_SAADC_RESOLUTION_12BIT,
					   &adv_cfg,
					   saadc_evt_handler);
	if (err != NRFX_SUCCESS) {
		printk("SAADC adv_mode_set err=0x%x\n", err);
		return -EIO;
	}

	/* Double-buffering to keep sampling continuous. */
	err = nrfx_saadc_buffer_set(saadc_buf[0], SAADC_BUF_SIZE);
	if (err != NRFX_SUCCESS) {
		printk("SAADC buf0 set err=0x%x (size=%u)\n", err, SAADC_BUF_SIZE);
		if (err == NRFX_ERROR_INVALID_LENGTH) {
			active_buf_size = 1;
			printk("SAADC retry buf0 with size=%u\n", active_buf_size);
			err = nrfx_saadc_buffer_set(saadc_buf[0], active_buf_size);
		}
		if (err != NRFX_SUCCESS) {
			printk("SAADC buf0 retry failed err=0x%x\n", err);
			return -EIO;
		}
	}
	err = nrfx_saadc_buffer_set(saadc_buf[1], active_buf_size);
	if (err != NRFX_SUCCESS) {
		printk("SAADC buf1 set err=0x%x (size=%u)\n", err, active_buf_size);
		return -EIO;
	}
	printk("SAADC buffers armed size=%u\n", active_buf_size);

	/* Timer drives SAADC sampling (PPI from TIMER2 compare[0] -> SAADC SAMPLE). */
	const uint32_t timer_base_hz = NRFX_TIMER_BASE_FREQUENCY_GET(emg_timer.p_reg);
	const uint32_t timer_target_hz = timer_base_hz; /* always valid; prescaler=0 */
	printk("TIMER base=%u Hz target=%u Hz\n", (unsigned int)timer_base_hz,
	       (unsigned int)timer_target_hz);

	nrfx_timer_config_t tcfg = NRFX_TIMER_DEFAULT_CONFIG(timer_target_hz);
	tcfg.bit_width = NRF_TIMER_BIT_WIDTH_32;
	printk("TIMER cfg: mode=%u bit_width=%u irq_prio=%u\n",
	       (unsigned int)tcfg.mode, (unsigned int)tcfg.bit_width,
	       (unsigned int)tcfg.interrupt_priority);
	err = nrfx_timer_init(&emg_timer, &tcfg, NULL);
	if (err != NRFX_SUCCESS) {
		printk("TIMER init err=0x%x\n", err);
		return -EIO;
	}

	/* Compare interval in microseconds for the requested fs. */
	uint32_t ticks = nrfx_timer_us_to_ticks(&emg_timer, 1000000U / CONFIG_EYE_ADC_SAMPLE_RATE_HZ);
	printk("TIMER ticks per sample=%u (fs=%u)\n", (unsigned int)ticks,
	       CONFIG_EYE_ADC_SAMPLE_RATE_HZ);
	nrfx_timer_clear(&emg_timer);
	nrfx_timer_extended_compare(&emg_timer, NRF_TIMER_CC_CHANNEL0, ticks,
				    NRF_TIMER_SHORT_COMPARE0_CLEAR_MASK, false);
	nrfx_timer_enable(&emg_timer);

	/* PPI: TIMER COMPARE -> SAADC SAMPLE. */
	err = nrfx_ppi_channel_alloc(&timer_saadc_ppi);
	if (err != NRFX_SUCCESS) {
		printk("PPI alloc timer->saadc err=0x%x\n", err);
		return -EIO;
	}
	err = nrfx_ppi_channel_assign(timer_saadc_ppi,
		nrfx_timer_compare_event_address_get(&emg_timer, NRF_TIMER_CC_CHANNEL0),
		nrf_saadc_task_address_get(NRF_SAADC, NRF_SAADC_TASK_SAMPLE));
	if (err != NRFX_SUCCESS) {
		printk("PPI assign timer->saadc err=0x%x\n", err);
		return -EIO;
	}
	err = nrfx_ppi_channel_enable(timer_saadc_ppi);
	if (err != NRFX_SUCCESS) {
		printk("PPI enable timer->saadc err=0x%x\n", err);
		return -EIO;
	}

	/* PPI: SAADC END -> START to keep sampling continuously with EasyDMA buffers. */
	/* PPI: SAADC END -> SAADC START for seamless DMA buffer cycling. */
	err = nrfx_ppi_channel_alloc(&saadc_start_ppi);
	if (err != NRFX_SUCCESS) {
		printk("PPI alloc end->start err=0x%x\n", err);
		return -EIO;
	}
	err = nrfx_ppi_channel_assign(saadc_start_ppi,
		nrf_saadc_event_address_get(NRF_SAADC, NRF_SAADC_EVENT_END),
		nrf_saadc_task_address_get(NRF_SAADC, NRF_SAADC_TASK_START));
	if (err != NRFX_SUCCESS) {
		printk("PPI assign end->start err=0x%x\n", err);
		return -EIO;
	}
	err = nrfx_ppi_channel_enable(saadc_start_ppi);
	if (err != NRFX_SUCCESS) {
		printk("PPI enable end->start err=0x%x\n", err);
		return -EIO;
	}

	/* Kick off first conversion; TIMER+PPI and END->START keep it running. */
	err = nrfx_saadc_mode_trigger();
	if (err != NRFX_SUCCESS) {
		printk("SAADC mode_trigger err=0x%x\n", err);
		return -EIO;
	}

	return 0;
}

uint32_t emg_sampler_get_latest_seq(void)
{
	return (uint32_t)atomic_get(&latest_seq);
}

uint16_t emg_sampler_get_latest_sample_u16(void)
{
	return (uint16_t)atomic_get(&latest_sample_u16);
}

uint32_t emg_sampler_get_latest_raw_seq(void)
{
	return (uint32_t)atomic_get(&latest_raw_seq);
}

uint16_t emg_sampler_get_latest_raw_u16(void)
{
	return (uint16_t)atomic_get(&latest_raw_u16);
}

int emg_sampler_get_uart_triple(struct emg_sample_triple *out, k_timeout_t timeout)
{
	if (!out) {
		return -EINVAL;
	}
	return k_msgq_get(&uart_sample_q, out, timeout);
}

uint16_t emg_sampler_get_latest_notch_u16(void)
{
	return (uint16_t)atomic_get(&latest_notch_u16);
}

uint32_t emg_sampler_get_uart_drop(void)
{
	return (uint32_t)atomic_get(&uart_q_drop);
}

uint32_t emg_sampler_get_uart_hwm(void)
{
	return (uint32_t)atomic_get(&uart_q_hwm);
}

uint32_t emg_sampler_pop_stream(uint32_t *first_seq, struct emg_stream_pair *dst,
				uint32_t max_samples)
{
	if (!first_seq || !dst || max_samples == 0) {
		return 0;
	}

	struct stream_item item;
	uint32_t count = 0;

	while (count < max_samples) {
		if (k_msgq_get(&stream_q, &item, K_NO_WAIT) != 0) {
			break;
		}

		if (count == 0) {
			*first_seq = item.seq;
		}
		dst[count].filtered = item.filtered;
		dst[count].envelope = item.envelope;
		count++;
	}

	return count;
}

uint32_t emg_sampler_get_stream_drop_count(void)
{
	return (uint32_t)atomic_get(&stream_drop);
}

uint32_t emg_sampler_get_clip_hi(void)
{
	return (uint32_t)atomic_get(&raw_clip_hi);
}

uint32_t emg_sampler_get_clip_lo(void)
{
	return (uint32_t)atomic_get(&raw_clip_lo);
}

/* End of file */
```

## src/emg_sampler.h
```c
/*
 * SPDX-License-Identifier: LicenseRef-Nordic-5-Clause
 */

#pragma once

#include <stdint.h>
#include <zephyr/kernel.h>

struct emg_sample_triple {
	/* Raw ADC sample after clipping to [0..4095]. */
	uint16_t raw;
	/* Filtered sample (notch + DC-block), re-centered to mid-scale. */
	uint16_t filtered;
	/* Notch-filter output before DC-block re-centering (exported as u16). */
	uint16_t notch;
	/* Envelope of the filtered signal (rectified + smoothed). */
	uint16_t envelope;
} __packed;

struct emg_stream_pair {
	/* Filtered sample (same as latest_sample_u16). */
	uint16_t filtered;
	/* Envelope value aligned to the same sample index. */
	uint16_t envelope;
} __packed;

/* Initialize SAADC sampling pipeline and filters. */
int emg_sampler_init(void);
/* Most recent decimated stream sequence number. */
uint32_t emg_sampler_get_latest_seq(void);
/* Most recent filtered (full-rate) sample in u16. */
uint16_t emg_sampler_get_latest_sample_u16(void);
/* Most recent raw sample sequence number. */
uint32_t emg_sampler_get_latest_raw_seq(void);
/* Most recent raw sample in u16. */
uint16_t emg_sampler_get_latest_raw_u16(void);
/* Pop one triple from the UART queue (full-rate). */
int emg_sampler_get_uart_triple(struct emg_sample_triple *out, k_timeout_t timeout);
/* Pop up to max_samples from the BLE stream queue. */
uint32_t emg_sampler_pop_stream(uint32_t *first_seq, struct emg_stream_pair *dst,
				uint32_t max_samples);
/* Stream queue drop counter (decimated BLE stream). */
uint32_t emg_sampler_get_stream_drop_count(void);
/* Raw clip counters for low/high saturation. */
uint32_t emg_sampler_get_clip_hi(void);
uint32_t emg_sampler_get_clip_lo(void);
/* Most recent notch output in u16. */
uint16_t emg_sampler_get_latest_notch_u16(void);
/* UART queue drop/high-water counters. */
uint32_t emg_sampler_get_uart_drop(void);
uint32_t emg_sampler_get_uart_hwm(void);
```

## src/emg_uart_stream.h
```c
/*
 * SPDX-License-Identifier: LicenseRef-Nordic-5-Clause
 */

#pragma once

/* Start the UART binary stream thread (no-op if disabled). */
int emg_uart_stream_init(void);
```
